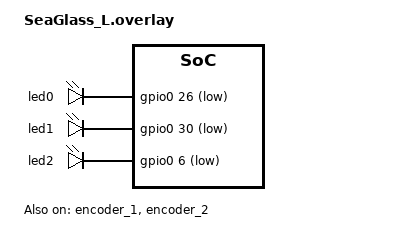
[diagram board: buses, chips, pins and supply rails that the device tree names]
#include "SeaGlass.dtsi"

&kscan_matrix {
        col-gpios
            = <&gpio0 28 GPIO_ACTIVE_HIGH>
            , <&gpio1 1 GPIO_ACTIVE_HIGH>
            , <&gpio0 29 GPIO_ACTIVE_HIGH>
            , <&gpio0 9 GPIO_ACTIVE_HIGH>
            , <&gpio0 4 GPIO_ACTIVE_HIGH>
            ;
};

&encoder_1 {
    status = "okay";
};


&encoder_2 {
    status = "okay";
};

/ {
    aliases {
        led-red = &led0;
        led-green = &led1;
        led-blue = &led2;
    };

    leds {
        compatible = "gpio-leds";
        status = "okay";
        led0: led_0 {
            gpios = <&gpio0 26 GPIO_ACTIVE_LOW>;  // red LED, connected to P0.26
        };
        led1: led_1 {
            gpios = <&gpio0 30 GPIO_ACTIVE_LOW>;  // green LED, connected to P0.30
        };
        led2: led_2 {
            gpios = <&gpio0 6 GPIO_ACTIVE_LOW>;  // blue LED, connected to P0.06
        };
    };
};
